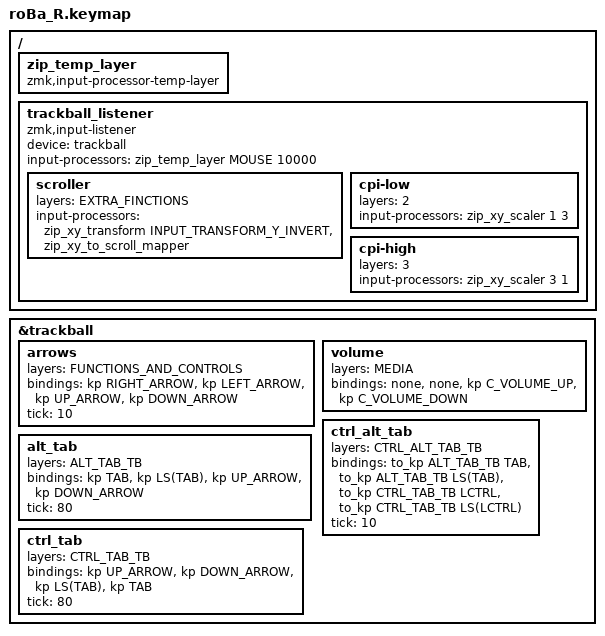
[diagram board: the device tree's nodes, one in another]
#include "roBa_L.keymap"

#include "boards/shields/Test/roBa_R.overlay"

#include <input/processors.dtsi>
#include <zephyr/dt-bindings/input/input-event-codes.h>
#include <dt-bindings/zmk/input_transform.h>

/ {
    zip_temp_layer: zip_temp_layer {
        compatible = "zmk,input-processor-temp-layer";
        #input-processor-cells = <2>;
        // excluded-positions = <18 19 21>;
    };

    trackball_listener {
        compatible = "zmk,input-listener";
        device = <&trackball>;

        input-processors = <&zip_temp_layer MOUSE 10000>;

        scroller {
            layers = <EXTRA_FINCTIONS>;
            input-processors =
                // <&zip_xy_scaler 3 2>,
                <&zip_xy_transform INPUT_TRANSFORM_Y_INVERT>,
                <&zip_xy_to_scroll_mapper>;
        };

        cpi-low {
            layers = <2>;
            input-processors = <&zip_xy_scaler 1 3>;
        };

        cpi-high {
            layers = <3>;
            input-processors = <&zip_xy_scaler 3 1>;
        };
    };
};

&trackball {
    arrows {
        layers = <FUNCTIONS_AND_CONTROLS>;
        bindings =
            <&kp RIGHT_ARROW>,
            <&kp LEFT_ARROW>,
            <&kp UP_ARROW>,
            <&kp DOWN_ARROW>;

        tick = <10>;
    };

    volume {
        layers = <MEDIA>;
        bindings =
            <&none>,
            <&none>,
            <&kp C_VOLUME_UP>,
            <&kp C_VOLUME_DOWN>;
    };

    ctrl_alt_tab {
        layers = <CTRL_ALT_TAB_TB>;
        bindings =
            <&to_kp ALT_TAB_TB TAB>,
            <&to_kp ALT_TAB_TB LS(TAB)>,
            <&to_kp CTRL_TAB_TB LCTRL>,
            <&to_kp CTRL_TAB_TB LS(LCTRL)>;
        tick = <10>;
    };

    alt_tab {
        layers = <ALT_TAB_TB>;
        bindings =
            <&kp TAB>,
            <&kp LS(TAB)>,
            <&kp UP_ARROW>,
            <&kp DOWN_ARROW>;

        tick = <80>;
    };

    ctrl_tab {
        layers = <CTRL_TAB_TB>;
        bindings =
            <&kp UP_ARROW>,
            <&kp DOWN_ARROW>,
            <&kp LS(TAB)>,
            <&kp TAB>;

        tick = <80>;
    };
};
